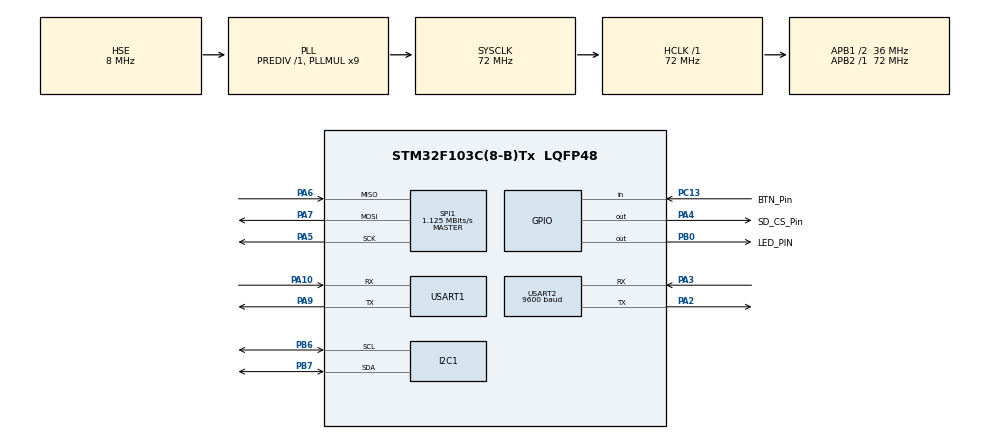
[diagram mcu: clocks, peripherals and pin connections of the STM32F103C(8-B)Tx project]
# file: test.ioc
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Dma.Request0=USART2_RX
Dma.USART2_RX.0.Direction=DMA_PERIPH_TO_MEMORY
Dma.USART2_RX.0.Instance=DMA1_Channel6
Dma.USART2_RX.0.MemDataAlignment=DMA_MDATAALIGN_BYTE
Dma.USART2_RX.0.MemInc=DMA_MINC_ENABLE
Dma.USART2_RX.0.Mode=DMA_NORMAL
Dma.USART2_RX.0.PeriphDataAlignment=DMA_PDATAALIGN_BYTE
Dma.USART2_RX.0.PeriphInc=DMA_PINC_DISABLE
Dma.USART2_RX.0.Priority=DMA_PRIORITY_MEDIUM
Mcu.Family=STM32F1
Mcu.Name=STM32F103C(8-B)Tx
Mcu.Package=LQFP48
NVIC.DMA1_Channel6_IRQn=true\:0\:0\:false\:false\:true\:false\:true\:true
NVIC.PriorityGroup=NVIC_PRIORITYGROUP_4
NVIC.USART1_IRQn=true\:0\:0\:false\:false\:true\:true\:true\:true
NVIC.USART2_IRQn=true\:0\:0\:false\:false\:true\:true\:true\:true
PA10.Mode=Asynchronous
PA10.Signal=USART1_RX
PA13.Mode=Serial_Wire
PA13.Signal=SYS_JTMS-SWDIO
PA14.Mode=Serial_Wire
PA14.Signal=SYS_JTCK-SWCLK
PA2.Mode=Asynchronous
PA2.Signal=USART2_TX
PA3.Mode=Asynchronous
PA3.Signal=USART2_RX
PA4.GPIO_Label=SD_CS_Pin
PA4.GPIO_Speed=GPIO_SPEED_FREQ_HIGH
PA4.Signal=GPIO_Output
PA5.Mode=Full_Duplex_Master
PA5.Signal=SPI1_SCK
PA6.Mode=Full_Duplex_Master
PA6.Signal=SPI1_MISO
PA7.Mode=Full_Duplex_Master
PA7.Signal=SPI1_MOSI
PA9.Mode=Asynchronous
PA9.Signal=USART1_TX
PB0.GPIO_Label=LED_PIN
PB0.Signal=GPIO_Output
PB6.Mode=I2C
PB6.Signal=I2C1_SCL
PB7.Mode=I2C
PB7.Signal=I2C1_SDA
PC13-TAMPER-RTC.GPIO_Label=BTN_Pin
PC13-TAMPER-RTC.GPIO_PuPd=GPIO_PULLUP
PC13-TAMPER-RTC.Signal=GPIO_Input
PD0-OSC_IN.Mode=HSE-External-Oscillator
PD0-OSC_IN.Signal=RCC_OSC_IN
PD1-OSC_OUT.Mode=HSE-External-Oscillator
PD1-OSC_OUT.Signal=RCC_OSC_OUT
ProjectManager.HeapSize=0x200
ProjectManager.StackSize=0x400
ProjectManager.TargetToolchain=STM32CubeIDE
RCC.AHBFreq_Value=72000000
RCC.APB1CLKDivider=RCC_HCLK_DIV2
RCC.APB1Freq_Value=36000000
RCC.APB1TimFreq_Value=72000000
RCC.APB2Freq_Value=72000000
RCC.APB2TimFreq_Value=72000000
RCC.HCLKFreq_Value=72000000
RCC.PLLMUL=RCC_PLL_MUL9
RCC.PLLSourceVirtual=RCC_PLLSOURCE_HSE
RCC.SYSCLKFreq_VALUE=72000000
RCC.SYSCLKSource=RCC_SYSCLKSOURCE_PLLCLK
RCC.USBFreq_Value=72000000
SPI1.BaudRatePrescaler=SPI_BAUDRATEPRESCALER_64
SPI1.CalculateBaudRate=1.125 MBits/s
SPI1.Direction=SPI_DIRECTION_2LINES
SPI1.Mode=SPI_MODE_MASTER
SPI1.VirtualType=VM_MASTER
USART1.VirtualMode=VM_ASYNC
USART2.BaudRate=9600
USART2.VirtualMode=VM_ASYNC
VP_FATFS_VS_Generic.Mode=User_defined
board=custom

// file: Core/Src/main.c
/* USER CODE BEGIN Header */
/**
  ******************************************************************************
  * @file           : main.c
  * @brief          : Main program body
  ******************************************************************************
  * @attention
  *
  * Copyright (c) 2026 STMicroelectronics.
  * All rights reserved.
  *
  * This software is licensed under terms that can be found in the LICENSE file
  * in the root directory of this software component.
  * If no LICENSE file comes with this software, it is provided AS-IS.
  *
  ******************************************************************************
  */
/* USER CODE END Header */
#include "main.h"
#include "fatfs.h"

/* USER CODE BEGIN Includes */
#include "app.h"
#include <stdio.h>
/* USER CODE END Includes */

I2C_HandleTypeDef hi2c1;

SPI_HandleTypeDef hspi1;

UART_HandleTypeDef huart1;
UART_HandleTypeDef huart2;
DMA_HandleTypeDef hdma_usart2_rx;

void SystemClock_Config(void);
static void MX_GPIO_Init(void);
static void MX_DMA_Init(void);
static void MX_I2C1_Init(void);
static void MX_SPI1_Init(void);
static void MX_USART1_UART_Init(void);
static void MX_USART2_UART_Init(void);
/* USER CODE BEGIN PFP */
void MX_FATFS_Init(void);

/* USER CODE END PFP */

int main(void)
{

  /* MCU Configuration--------------------------------------------------------*/

  /* Reset of all peripherals, Initializes the Flash interface and the Systick. */
  HAL_Init();

  /* Configure the system clock */
  SystemClock_Config();

  /* Initialize all configured peripherals */
  MX_GPIO_Init();
  MX_DMA_Init();
  MX_I2C1_Init();
  MX_SPI1_Init();
  MX_USART1_UART_Init();
  MX_USART2_UART_Init();
  MX_FATFS_Init();
  /* USER CODE BEGIN 2 */
  APP_Init();

  /* USER CODE END 2 */

  /* Infinite loop */
  while (1)
  {
	  APP_Run();
  }
}

void SystemClock_Config(void)
{
  RCC_OscInitTypeDef RCC_OscInitStruct = {0};
  RCC_ClkInitTypeDef RCC_ClkInitStruct = {0};

  /** Initializes the RCC Oscillators according to the specified parameters
  * in the RCC_OscInitTypeDef structure.
  */
  RCC_OscInitStruct.OscillatorType = RCC_OSCILLATORTYPE_HSE;
  RCC_OscInitStruct.HSEState = RCC_HSE_ON;
  RCC_OscInitStruct.HSEPredivValue = RCC_HSE_PREDIV_DIV1;
  RCC_OscInitStruct.HSIState = RCC_HSI_ON;
  RCC_OscInitStruct.PLL.PLLState = RCC_PLL_ON;
  RCC_OscInitStruct.PLL.PLLSource = RCC_PLLSOURCE_HSE;
  RCC_OscInitStruct.PLL.PLLMUL = RCC_PLL_MUL9;
  if (HAL_RCC_OscConfig(&RCC_OscInitStruct) != HAL_OK)
  {
    Error_Handler();
  }

  /** Initializes the CPU, AHB and APB buses clocks
  */
  RCC_ClkInitStruct.ClockType = RCC_CLOCKTYPE_HCLK|RCC_CLOCKTYPE_SYSCLK
                              |RCC_CLOCKTYPE_PCLK1|RCC_CLOCKTYPE_PCLK2;
  RCC_ClkInitStruct.SYSCLKSource = RCC_SYSCLKSOURCE_PLLCLK;
  RCC_ClkInitStruct.AHBCLKDivider = RCC_SYSCLK_DIV1;
  RCC_ClkInitStruct.APB1CLKDivider = RCC_HCLK_DIV2;
  RCC_ClkInitStruct.APB2CLKDivider = RCC_HCLK_DIV1;

  if (HAL_RCC_ClockConfig(&RCC_ClkInitStruct, FLASH_LATENCY_2) != HAL_OK)
  {
    Error_Handler();
  }
}

static void MX_I2C1_Init(void)
{

  hi2c1.Instance = I2C1;
  hi2c1.Init.ClockSpeed = 100000;
  hi2c1.Init.DutyCycle = I2C_DUTYCYCLE_2;
  hi2c1.Init.OwnAddress1 = 0;
  hi2c1.Init.AddressingMode = I2C_ADDRESSINGMODE_7BIT;
  hi2c1.Init.DualAddressMode = I2C_DUALADDRESS_DISABLE;
  hi2c1.Init.OwnAddress2 = 0;
  hi2c1.Init.GeneralCallMode = I2C_GENERALCALL_DISABLE;
  hi2c1.Init.NoStretchMode = I2C_NOSTRETCH_DISABLE;
  if (HAL_I2C_Init(&hi2c1) != HAL_OK)
  {
    Error_Handler();
  }

}

static void MX_SPI1_Init(void)
{

  /* SPI1 parameter configuration*/
  hspi1.Instance = SPI1;
  hspi1.Init.Mode = SPI_MODE_MASTER;
  hspi1.Init.Direction = SPI_DIRECTION_2LINES;
  hspi1.Init.DataSize = SPI_DATASIZE_8BIT;
  hspi1.Init.CLKPolarity = SPI_POLARITY_LOW;
  hspi1.Init.CLKPhase = SPI_PHASE_1EDGE;
  hspi1.Init.NSS = SPI_NSS_SOFT;
  hspi1.Init.BaudRatePrescaler = SPI_BAUDRATEPRESCALER_64;
  hspi1.Init.FirstBit = SPI_FIRSTBIT_MSB;
  hspi1.Init.TIMode = SPI_TIMODE_DISABLE;
  hspi1.Init.CRCCalculation = SPI_CRCCALCULATION_DISABLE;
  hspi1.Init.CRCPolynomial = 10;
  if (HAL_SPI_Init(&hspi1) != HAL_OK)
  {
    Error_Handler();
  }

}

static void MX_USART1_UART_Init(void)
{

  huart1.Instance = USART1;
  huart1.Init.BaudRate = 115200;
  huart1.Init.WordLength = UART_WORDLENGTH_8B;
  huart1.Init.StopBits = UART_STOPBITS_1;
  huart1.Init.Parity = UART_PARITY_NONE;
  huart1.Init.Mode = UART_MODE_TX_RX;
  huart1.Init.HwFlowCtl = UART_HWCONTROL_NONE;
  huart1.Init.OverSampling = UART_OVERSAMPLING_16;
  if (HAL_UART_Init(&huart1) != HAL_OK)
  {
    Error_Handler();
  }

}

static void MX_USART2_UART_Init(void)
{

  huart2.Instance = USART2;
  huart2.Init.BaudRate = 9600;
  huart2.Init.WordLength = UART_WORDLENGTH_8B;
  huart2.Init.StopBits = UART_STOPBITS_1;
  huart2.Init.Parity = UART_PARITY_NONE;
  huart2.Init.Mode = UART_MODE_TX_RX;
  huart2.Init.HwFlowCtl = UART_HWCONTROL_NONE;
  huart2.Init.OverSampling = UART_OVERSAMPLING_16;
  if (HAL_UART_Init(&huart2) != HAL_OK)
  {
    Error_Handler();
  }

}

static void MX_DMA_Init(void)
{

  /* DMA controller clock enable */
  __HAL_RCC_DMA1_CLK_ENABLE();

  /* DMA interrupt init */
  /* DMA1_Channel6_IRQn interrupt configuration */
  HAL_NVIC_SetPriority(DMA1_Channel6_IRQn, 0, 0);
  HAL_NVIC_EnableIRQ(DMA1_Channel6_IRQn);

}

static void MX_GPIO_Init(void)
{
  GPIO_InitTypeDef GPIO_InitStruct = {0};

  /* GPIO Ports Clock Enable */
  __HAL_RCC_GPIOC_CLK_ENABLE();
  __HAL_RCC_GPIOD_CLK_ENABLE();
  __HAL_RCC_GPIOA_CLK_ENABLE();
  __HAL_RCC_GPIOB_CLK_ENABLE();

  /*Configure GPIO pin Output Level */
  HAL_GPIO_WritePin(SD_CS_Pin_GPIO_Port, SD_CS_Pin_Pin, GPIO_PIN_RESET);

  /*Configure GPIO pin Output Level */
  HAL_GPIO_WritePin(LED_PIN_GPIO_Port, LED_PIN_Pin, GPIO_PIN_RESET);

  /*Configure GPIO pin : BTN_Pin_Pin */
  GPIO_InitStruct.Pin = BTN_Pin_Pin;
  GPIO_InitStruct.Mode = GPIO_MODE_INPUT;
  GPIO_InitStruct.Pull = GPIO_PULLUP;
  HAL_GPIO_Init(BTN_Pin_GPIO_Port, &GPIO_InitStruct);

  /*Configure GPIO pin : SD_CS_Pin_Pin */
  GPIO_InitStruct.Pin = SD_CS_Pin_Pin;
  GPIO_InitStruct.Mode = GPIO_MODE_OUTPUT_PP;
  GPIO_InitStruct.Pull = GPIO_NOPULL;
  GPIO_InitStruct.Speed = GPIO_SPEED_FREQ_HIGH;
  HAL_GPIO_Init(SD_CS_Pin_GPIO_Port, &GPIO_InitStruct);

  /*Configure GPIO pin : LED_PIN_Pin */
  GPIO_InitStruct.Pin = LED_PIN_Pin;
  GPIO_InitStruct.Mode = GPIO_MODE_OUTPUT_PP;
  GPIO_InitStruct.Pull = GPIO_NOPULL;
  GPIO_InitStruct.Speed = GPIO_SPEED_FREQ_LOW;
  HAL_GPIO_Init(LED_PIN_GPIO_Port, &GPIO_InitStruct);

}

void Error_Handler(void)
{
  __disable_irq();
  while (1)
  {
  }
}
